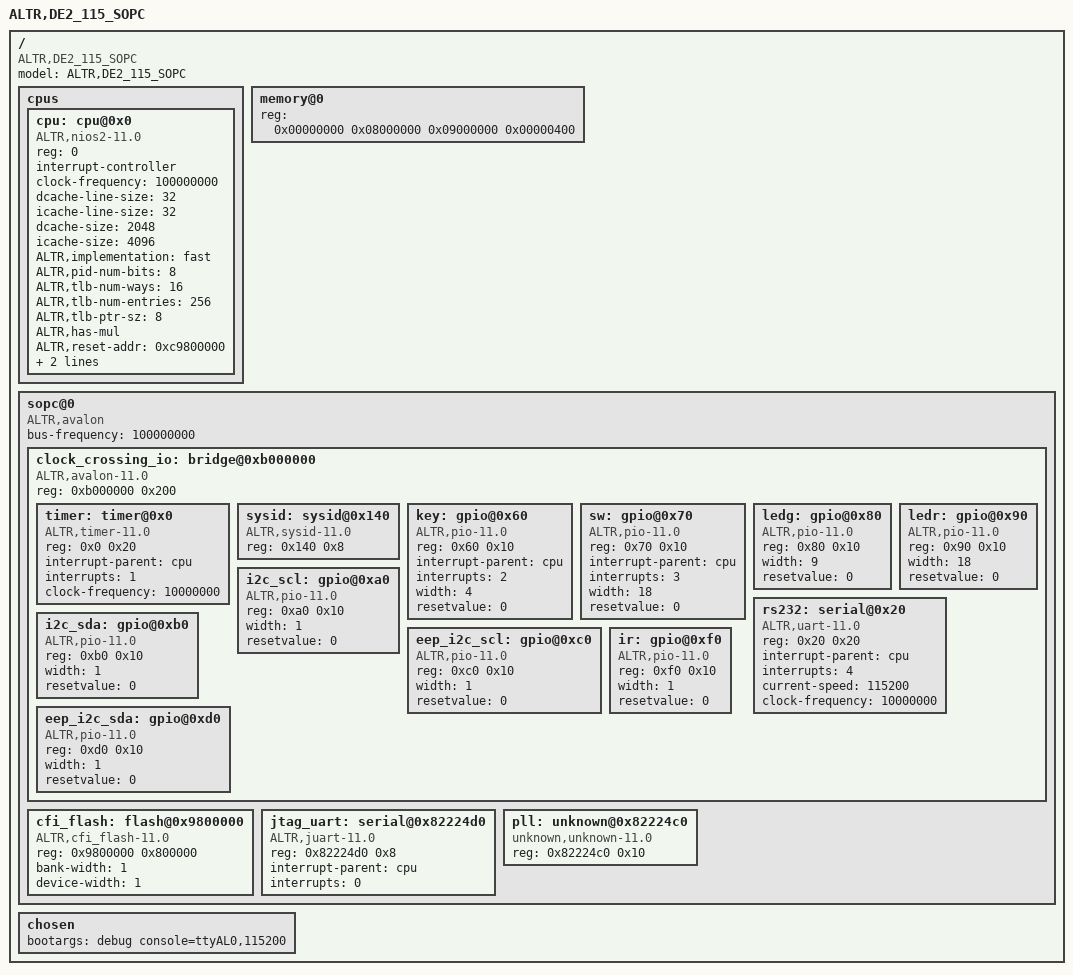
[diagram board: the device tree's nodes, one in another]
/*
 * This devicetree is generated by sopc2dts
 * Sopc2dts is written by Walter Goossens <waltergoossens@home.nl>
 * in cooperation with the nios2 community <Nios2-dev@sopc.et.ntust.edu.tw>
 */
/dts-v1/;
/ {
	model = "ALTR,DE2_115_SOPC";
	compatible = "ALTR,DE2_115_SOPC";
	#address-cells = <1>;
	#size-cells = <1>;
	cpus {
		#address-cells = <1>;
		#size-cells = <0>;
		cpu: cpu@0x0 {
			device_type = "cpu";
			compatible = "ALTR,nios2-11.0";
			reg = <0>;
			interrupt-controller;
			#interrupt-cells = <1>;
			clock-frequency = <100000000>;	//embeddedsw.CMacro.CPU_FREQ type NUMBER
			dcache-line-size = <32>;	//embeddedsw.CMacro.DCACHE_LINE_SIZE type NUMBER
			icache-line-size = <32>;	//embeddedsw.CMacro.ICACHE_LINE_SIZE type NUMBER
			dcache-size = <2048>;	//embeddedsw.CMacro.DCACHE_SIZE type NUMBER
			icache-size = <4096>;	//embeddedsw.CMacro.ICACHE_SIZE type NUMBER
			ALTR,implementation = "fast";	//embeddedsw.CMacro.CPU_IMPLEMENTATION type STRING
			ALTR,pid-num-bits = <8>;	//embeddedsw.CMacro.PROCESS_ID_NUM_BITS type NUMBER
			ALTR,tlb-num-ways = <16>;	//embeddedsw.CMacro.TLB_NUM_WAYS type NUMBER
			ALTR,tlb-num-entries = <256>;	//embeddedsw.CMacro.TLB_NUM_ENTRIES type NUMBER
			ALTR,tlb-ptr-sz = <8>;	//embeddedsw.CMacro.TLB_PTR_SZ type NUMBER
			ALTR,has-mul;	//embeddedsw.CMacro.HARDWARE_MULTIPLY_PRESENT type NUMBER
			ALTR,reset-addr = <0xc9800000>;	//embeddedsw.CMacro.RESET_ADDR type NUMBER
			ALTR,fast-tlb-miss-addr = <0xc9000000>;	//embeddedsw.CMacro.FAST_TLB_MISS_EXCEPTION_ADDR type NUMBER
			ALTR,exception-addr = <0xc0000020>;	//embeddedsw.CMacro.EXCEPTION_ADDR type NUMBER
		};
	};
	memory@0 {
		device_type = "memory";
		reg = <0x00000000 0x08000000
			0x09000000 0x00000400>;
	};
	sopc@0 {
		ranges ;
		#address-cells = <1>;
		#size-cells = <1>;
		device_type = "soc";
		compatible = "ALTR,avalon","simple-bus";
		bus-frequency = < 100000000 >;
		//Port instruction_master of cpu
		clock_crossing_io: bridge@0xb000000 {
			compatible = "ALTR,avalon-11.0","simple-bus";
			reg = < 0xb000000 0x200>;
			#address-cells = <1>;
			#size-cells = <1>;
			ranges = <0x00000000 0x0B000000 0x00000020
				0x00000140 0x0B000140 0x00000008
				0x00000060 0x0B000060 0x00000010
				0x00000070 0x0B000070 0x00000010
				0x00000080 0x0B000080 0x00000010
				0x00000090 0x0B000090 0x00000010
				0x00000020 0x0B000020 0x00000020
				0x000000A0 0x0B0000A0 0x00000010
				0x000000B0 0x0B0000B0 0x00000010
				0x000000C0 0x0B0000C0 0x00000010
				0x000000D0 0x0B0000D0 0x00000010
				0x000000F0 0x0B0000F0 0x00000010>;

			//Port m1 of clock_crossing_io
			timer: timer@0x0 {
				compatible = "ALTR,timer-11.0","ALTR,timer-1.0";
				reg = < 0x0 0x20>;
				interrupt-parent = < &cpu >;
				interrupts = < 1 >;
				clock-frequency = <10000000>;
			}; //end timer (timer)

			sysid: sysid@0x140 {
				compatible = "ALTR,sysid-11.0","ALTR,sysid-1.0";
				reg = < 0x140 0x8>;
			}; //end sysid (sysid)

			key: gpio@0x60 {
				compatible = "ALTR,pio-11.0","ALTR,pio-1.0";
				reg = < 0x60 0x10>;
				interrupt-parent = < &cpu >;
				interrupts = < 2 >;
				width = <4>;	//width type NUMBER
				resetvalue = <0>;	//resetValue type NUMBER
			}; //end gpio (key)

			sw: gpio@0x70 {
				compatible = "ALTR,pio-11.0","ALTR,pio-1.0";
				reg = < 0x70 0x10>;
				interrupt-parent = < &cpu >;
				interrupts = < 3 >;
				width = <18>;	//width type NUMBER
				resetvalue = <0>;	//resetValue type NUMBER
			}; //end gpio (sw)

			ledg: gpio@0x80 {
				compatible = "ALTR,pio-11.0","ALTR,pio-1.0";
				reg = < 0x80 0x10>;
				width = <9>;	//width type NUMBER
				resetvalue = <0>;	//resetValue type NUMBER
			}; //end gpio (ledg)

			ledr: gpio@0x90 {
				compatible = "ALTR,pio-11.0","ALTR,pio-1.0";
				reg = < 0x90 0x10>;
				width = <18>;	//width type NUMBER
				resetvalue = <0>;	//resetValue type NUMBER
			}; //end gpio (ledr)

			rs232: serial@0x20 {
				compatible = "ALTR,uart-11.0","ALTR,uart-1.0";
				reg = < 0x20 0x20>;
				interrupt-parent = < &cpu >;
				interrupts = < 4 >;
				current-speed = <115200>;	//embeddedsw.CMacro.BAUD type NUMBER
				clock-frequency = <10000000>;	//embeddedsw.CMacro.FREQ type NUMBER
			}; //end serial (rs232)

			i2c_scl: gpio@0xa0 {
				compatible = "ALTR,pio-11.0","ALTR,pio-1.0";
				reg = < 0xa0 0x10>;
				width = <1>;	//width type NUMBER
				resetvalue = <0>;	//resetValue type NUMBER
			}; //end gpio (i2c_scl)

			i2c_sda: gpio@0xb0 {
				compatible = "ALTR,pio-11.0","ALTR,pio-1.0";
				reg = < 0xb0 0x10>;
				width = <1>;	//width type NUMBER
				resetvalue = <0>;	//resetValue type NUMBER
			}; //end gpio (i2c_sda)

			eep_i2c_scl: gpio@0xc0 {
				compatible = "ALTR,pio-11.0","ALTR,pio-1.0";
				reg = < 0xc0 0x10>;
				width = <1>;	//width type NUMBER
				resetvalue = <0>;	//resetValue type NUMBER
			}; //end gpio (eep_i2c_scl)

			eep_i2c_sda: gpio@0xd0 {
				compatible = "ALTR,pio-11.0","ALTR,pio-1.0";
				reg = < 0xd0 0x10>;
				width = <1>;	//width type NUMBER
				resetvalue = <0>;	//resetValue type NUMBER
			}; //end gpio (eep_i2c_sda)

			ir: gpio@0xf0 {
				compatible = "ALTR,pio-11.0","ALTR,pio-1.0";
				reg = < 0xf0 0x10>;
				width = <1>;	//width type NUMBER
				resetvalue = <0>;	//resetValue type NUMBER
			}; //end gpio (ir)

		}; //end bridge (clock_crossing_io)

		cfi_flash: flash@0x9800000 {
			compatible = "ALTR,cfi_flash-11.0","cfi-flash";
			reg = < 0x9800000 0x800000>;
			bank-width = <1>;
			device-width = <1>;
		}; //end flash (cfi_flash)

		//Port tightly_coupled_instruction_master_0 of cpu
		//Port data_master of cpu
		jtag_uart: serial@0x82224d0 {
			compatible = "ALTR,juart-11.0","ALTR,juart-1.0";
			reg = < 0x82224d0 0x8>;
			interrupt-parent = < &cpu >;
			interrupts = < 0 >;
		}; //end serial (jtag_uart)

		pll: unknown@0x82224c0 {
			compatible = "unknown,unknown-11.0";
			reg = < 0x82224c0 0x10>;
		}; //end unknown (pll)

		//Port tightly_coupled_data_master_0 of cpu
	}; //sopc
	chosen {
		bootargs = "debug console=ttyAL0,115200";
	};
};
